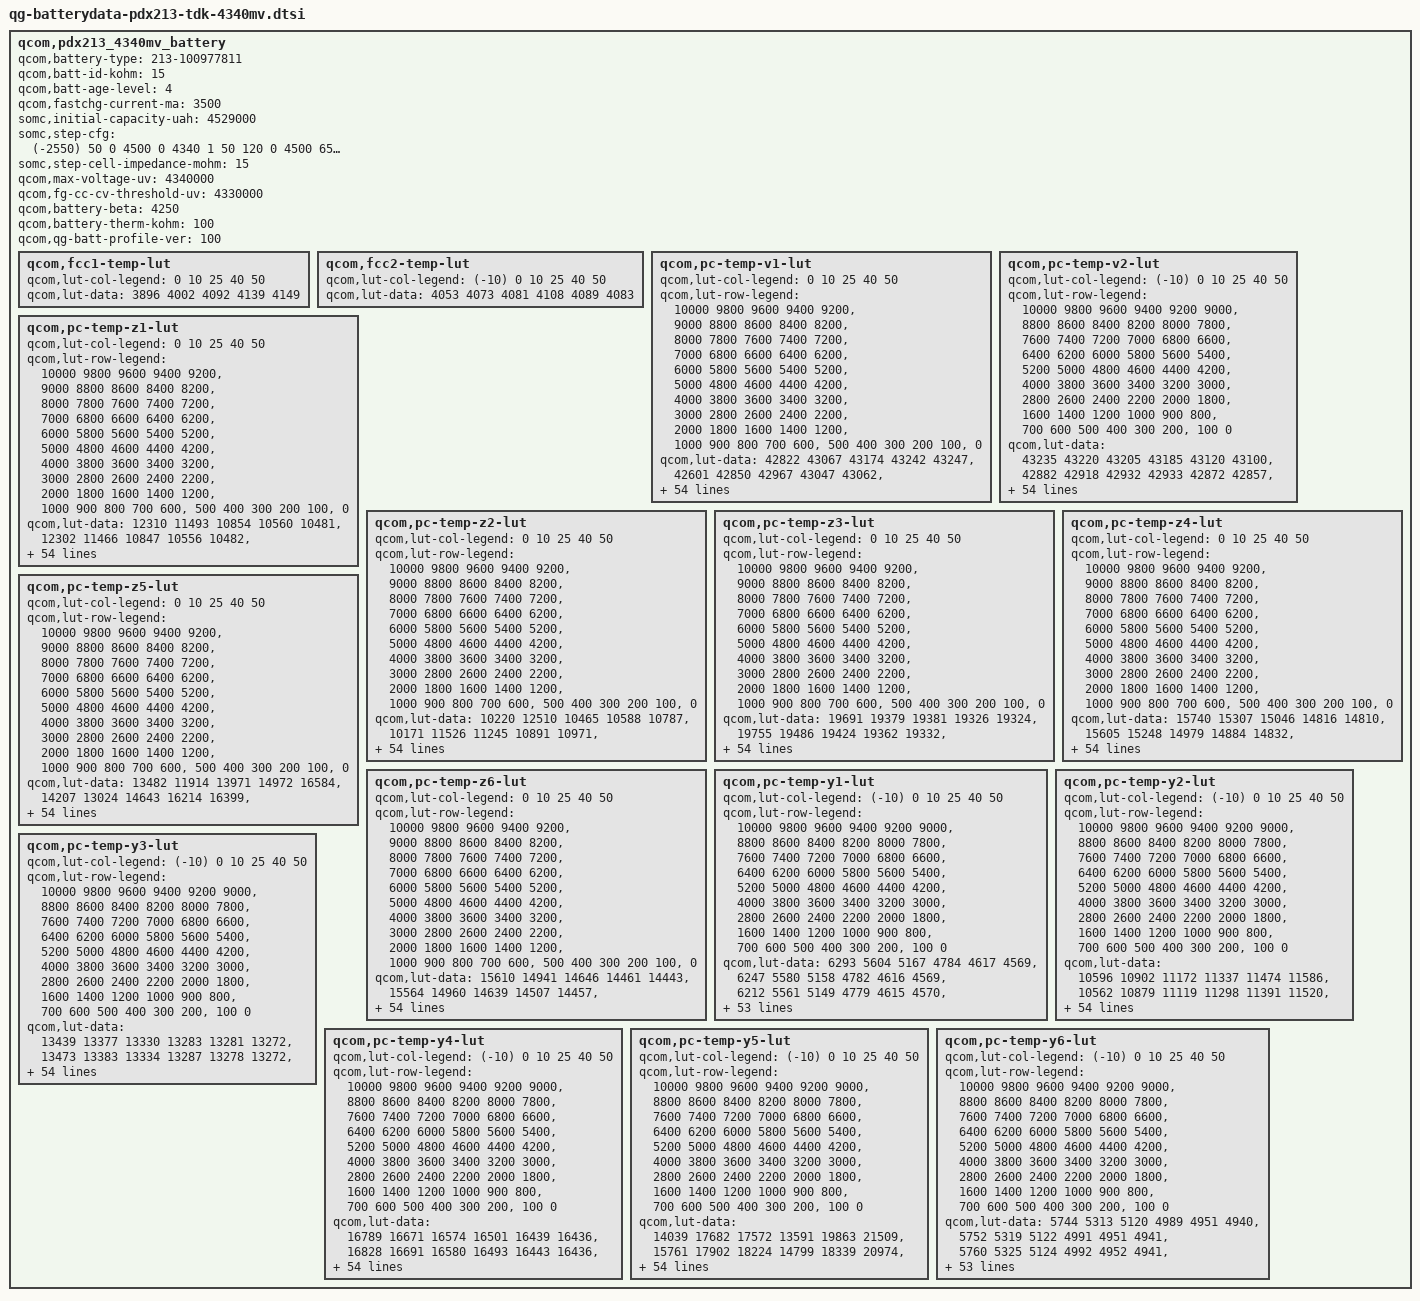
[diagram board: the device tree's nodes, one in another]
qcom,pdx213_4340mv_battery {
	/* Added or Modified by SOMC */
	qcom,battery-type = "213-100977811";
	qcom,batt-id-kohm = <15>;
	qcom,batt-age-level = <4>;
	qcom,fastchg-current-ma = <3500>;
	somc,initial-capacity-uah = <4529000>;
	somc,step-cfg = <
		(-2550) 50    0 4500    0 4340 1
		   50  120    0 4500  650 4340 2
		  120  150    0 4100 1950 4340 3
		  120  150 4100 4200 1500 4340 3
		  120  150 4200 4500  850 4340 3
		  150  200    0 4100 2150 4340 3
		  150  200 4100 4200 1750 4340 3
		  150  200 4200 4300 1500 4340 3
		  150  200 4300 4500 1050 4340 3
		  200  450    0 4150 3250 4340 3
		  200  450 4150 4200 2400 4340 3
		  200  450 4200 4300 1300 4340 3
		  200  450 4300 4500 1050 4340 3
		  450  550    0 4500 1300 4200 4
		  550 2550    0 4500    0 4200 5
	>;
	somc,step-cell-impedance-mohm = <15>;

	/* Prepared by Qualcomm */
    /* 4764147_SoMC_Licht_4129mAh_averaged_MasterSlave_Sept1st2020 */
    qcom,max-voltage-uv = <4340000>;
    qcom,fg-cc-cv-threshold-uv = <4330000>;
    /* qcom,fastchg-current-ma = <1500>; */
    /* qcom,batt-id-kohm = <0>; */
    qcom,battery-beta = <4250>;
    qcom,battery-therm-kohm = <100>;
    /* qcom,battery-type = "4764147_SoMC_Licht_4129mAh_averaged_MasterSlave_Sept1st2020"; */
    qcom,qg-batt-profile-ver = <100>;

	qcom,fcc1-temp-lut {
		qcom,lut-col-legend = <0 10 25 40 50>;
		qcom,lut-data = <3896 4002 4092 4139 4149>;
	};

	qcom,fcc2-temp-lut {
		qcom,lut-col-legend = <(-10) 0 10 25 40 50>;
		qcom,lut-data = <4053 4073 4081 4108 4089 4083>;
	};

	qcom,pc-temp-v1-lut {
		qcom,lut-col-legend = <0 10 25 40 50>;
		qcom,lut-row-legend = <10000 9800 9600 9400 9200>,
			<9000 8800 8600 8400 8200>,
			<8000 7800 7600 7400 7200>,
			<7000 6800 6600 6400 6200>,
			<6000 5800 5600 5400 5200>,
			<5000 4800 4600 4400 4200>,
			<4000 3800 3600 3400 3200>,
			<3000 2800 2600 2400 2200>,
			<2000 1800 1600 1400 1200>,
			<1000 900 800 700 600>,
			<500 400 300 200 100>,
			<0>;
		qcom,lut-data = <42822 43067 43174 43242 43247>,
			<42601 42850 42967 43047 43062>,
			<42385 42622 42754 42833 42849>,
			<42175 42391 42530 42618 42633>,
			<41968 42170 42302 42398 42415>,
			<41765 41955 42081 42176 42195>,
			<41565 41746 41866 41957 41977>,
			<41369 41540 41655 41738 41760>,
			<41181 41341 41450 41526 41547>,
			<41002 41146 41247 41318 41339>,
			<40826 40958 41049 41115 41135>,
			<40641 40774 40855 40917 40937>,
			<40451 40593 40666 40723 40742>,
			<40277 40414 40487 40539 40556>,
			<40126 40248 40315 40362 40377>,
			<39986 40102 40151 40192 40205>,
			<39851 39962 40001 40037 40045>,
			<39726 39812 39848 39887 39894>,
			<39596 39656 39668 39713 39724>,
			<39445 39482 39468 39501 39523>,
			<39277 39244 39276 39297 39323>,
			<39113 38986 39079 39122 39143>,
			<38942 38842 38909 38966 38977>,
			<38786 38769 38801 38835 38839>,
			<38688 38710 38721 38727 38726>,
			<38621 38648 38641 38629 38627>,
			<38568 38589 38555 38538 38535>,
			<38525 38528 38474 38452 38450>,
			<38488 38467 38405 38375 38370>,
			<38452 38406 38342 38302 38294>,
			<38412 38352 38287 38238 38224>,
			<38373 38302 38236 38180 38161>,
			<38336 38256 38190 38128 38103>,
			<38301 38217 38145 38077 38045>,
			<38265 38182 38103 38030 37991>,
			<38229 38142 38059 37980 37934>,
			<38190 38103 38018 37924 37867>,
			<38137 38054 37972 37861 37794>,
			<38051 37974 37903 37787 37714>,
			<37942 37862 37799 37697 37626>,
			<37824 37742 37683 37595 37526>,
			<37689 37611 37556 37473 37402>,
			<37541 37467 37417 37336 37265>,
			<37384 37304 37258 37184 37118>,
			<37266 37186 37136 37069 37009>,
			<37185 37119 37072 37008 36948>,
			<37166 37098 37054 36994 36931>,
			<37148 37078 37040 36979 36918>,
			<37115 37053 37022 36959 36902>,
			<37051 37000 36966 36894 36824>,
			<36830 36760 36701 36604 36516>,
			<36386 36326 36271 36173 36085>,
			<35820 35763 35715 35615 35530>,
			<35053 34997 34964 34863 34782>,
			<33752 33749 33817 33717 33648>,
			<30000 30000 30000 30000 30000>;
	};

	qcom,pc-temp-v2-lut {
		qcom,lut-col-legend = <(-10) 0 10 25 40 50>;
		qcom,lut-row-legend = <10000 9800 9600 9400 9200 9000>,
			<8800 8600 8400 8200 8000 7800>,
			<7600 7400 7200 7000 6800 6600>,
			<6400 6200 6000 5800 5600 5400>,
			<5200 5000 4800 4600 4400 4200>,
			<4000 3800 3600 3400 3200 3000>,
			<2800 2600 2400 2200 2000 1800>,
			<1600 1400 1200 1000 900 800>,
			<700 600 500 400 300 200>,
			<100 0>;
		qcom,lut-data = <43235 43220 43205 43185 43120 43100>,
			<42882 42918 42932 42933 42872 42857>,
			<42563 42638 42673 42691 42633 42623>,
			<42283 42380 42430 42459 42403 42396>,
			<42041 42145 42204 42238 42183 42177>,
			<41806 41920 41983 42020 41968 41962>,
			<41542 41698 41763 41803 41754 41747>,
			<41282 41483 41547 41588 41543 41536>,
			<41105 41275 41337 41378 41337 41330>,
			<41002 41071 41130 41171 41134 41126>,
			<40888 40878 40930 40970 40935 40928>,
			<40653 40704 40738 40776 40742 40737>,
			<40312 40540 40553 40587 40555 40551>,
			<40045 40362 40375 40404 40375 40372>,
			<39859 40166 40210 40226 40202 40198>,
			<39687 39962 40039 40055 40035 40030>,
			<39490 39746 39838 39899 39881 39875>,
			<39281 39522 39618 39746 39731 39726>,
			<39074 39309 39405 39559 39550 39548>,
			<38860 39104 39193 39318 39314 39316>,
			<38661 38913 38999 39090 39087 39092>,
			<38504 38747 38840 38914 38918 38924>,
			<38368 38600 38703 38764 38776 38783>,
			<38266 38463 38579 38636 38654 38662>,
			<38196 38332 38467 38528 38549 38558>,
			<38141 38215 38365 38432 38455 38465>,
			<38087 38118 38272 38342 38367 38376>,
			<38036 38034 38188 38259 38287 38292>,
			<37987 37971 38106 38181 38212 38215>,
			<37939 37929 38024 38108 38142 38143>,
			<37892 37894 37949 38041 38078 38077>,
			<37843 37861 37885 37982 38017 38016>,
			<37791 37831 37830 37928 37962 37960>,
			<37736 37797 37784 37871 37897 37892>,
			<37681 37759 37752 37816 37815 37793>,
			<37624 37715 37721 37758 37726 37684>,
			<37559 37660 37682 37688 37639 37588>,
			<37482 37587 37636 37609 37551 37500>,
			<37399 37504 37577 37528 37464 37412>,
			<37308 37411 37492 37449 37383 37329>,
			<37210 37306 37384 37361 37299 37244>,
			<37116 37185 37264 37252 37190 37136>,
			<37030 37041 37124 37126 37062 37005>,
			<36944 36911 36982 36986 36947 36894>,
			<36858 36799 36856 36899 36868 36816>,
			<36761 36720 36793 36868 36846 36798>,
			<36708 36688 36765 36853 36833 36782>,
			<36652 36649 36734 36831 36809 36763>,
			<36583 36598 36670 36792 36783 36735>,
			<36484 36496 36564 36679 36673 36599>,
			<36306 36248 36284 36365 36322 36237>,
			<35949 35794 35802 35871 35841 35757>,
			<35380 35141 35159 35239 35213 35132>,
			<34490 34190 34290 34362 34365 34280>,
			<33143 32720 32916 33184 33128 33134>,
			<31124 29569 29519 29613 29671 29810>;
	};

	qcom,pc-temp-z1-lut {
		qcom,lut-col-legend = <0 10 25 40 50>;
		qcom,lut-row-legend = <10000 9800 9600 9400 9200>,
			<9000 8800 8600 8400 8200>,
			<8000 7800 7600 7400 7200>,
			<7000 6800 6600 6400 6200>,
			<6000 5800 5600 5400 5200>,
			<5000 4800 4600 4400 4200>,
			<4000 3800 3600 3400 3200>,
			<3000 2800 2600 2400 2200>,
			<2000 1800 1600 1400 1200>,
			<1000 900 800 700 600>,
			<500 400 300 200 100>,
			<0>;
		qcom,lut-data = <12310 11493 10854 10560 10481>,
			<12302 11466 10847 10556 10482>,
			<12291 11465 10841 10556 10481>,
			<12272 11465 10834 10555 10480>,
			<12239 11464 10827 10553 10479>,
			<12214 11453 10825 10552 10479>,
			<12211 11438 10824 10551 10478>,
			<12216 11423 10823 10550 10478>,
			<12212 11407 10822 10549 10478>,
			<12175 11402 10820 10549 10478>,
			<12141 11406 10820 10549 10479>,
			<12141 11411 10821 10549 10479>,
			<12144 11409 10822 10550 10480>,
			<12147 11400 10821 10550 10481>,
			<12152 11396 10820 10551 10481>,
			<12160 11396 10821 10552 10482>,
			<12163 11397 10823 10553 10483>,
			<12160 11398 10826 10555 10485>,
			<12157 11404 10829 10557 10486>,
			<12159 11410 10833 10558 10488>,
			<12167 11416 10837 10561 10490>,
			<12171 11424 10841 10563 10493>,
			<12169 11432 10846 10566 10496>,
			<12166 11442 10852 10569 10499>,
			<12170 11450 10857 10573 10501>,
			<12183 11447 10862 10576 10502>,
			<12193 11441 10866 10579 10504>,
			<12187 11438 10870 10582 10506>,
			<12174 11445 10875 10584 10507>,
			<12169 11455 10880 10587 10509>,
			<12182 11459 10884 10589 10512>,
			<12201 11465 10885 10591 10514>,
			<12208 11468 10886 10594 10516>,
			<12215 11468 10888 10596 10518>,
			<12218 11470 10891 10599 10519>,
			<12224 11476 10896 10601 10521>,
			<12236 11490 10902 10604 10523>,
			<12242 11502 10909 10607 10526>,
			<12253 11507 10916 10610 10528>,
			<12266 11513 10924 10612 10529>,
			<12272 11514 10929 10614 10530>,
			<12290 11514 10930 10617 10533>,
			<12293 11518 10932 10620 10535>,
			<12290 11538 10940 10623 10536>,
			<12320 11545 10948 10626 10538>,
			<12324 11528 10950 10627 10538>,
			<12323 11539 10956 10628 10540>,
			<12322 11544 10959 10630 10540>,
			<12321 11561 10953 10630 10541>,
			<12320 11551 10967 10635 10544>,
			<12321 11567 10979 10641 10550>,
			<12323 11586 10990 10651 10559>,
			<12387 11634 11011 10665 10570>,
			<12408 11666 11046 10687 10587>,
			<12408 11666 11046 10687 10587>,
			<12408 11666 11046 10687 10587>;
	};

	qcom,pc-temp-z2-lut {
		qcom,lut-col-legend = <0 10 25 40 50>;
		qcom,lut-row-legend = <10000 9800 9600 9400 9200>,
			<9000 8800 8600 8400 8200>,
			<8000 7800 7600 7400 7200>,
			<7000 6800 6600 6400 6200>,
			<6000 5800 5600 5400 5200>,
			<5000 4800 4600 4400 4200>,
			<4000 3800 3600 3400 3200>,
			<3000 2800 2600 2400 2200>,
			<2000 1800 1600 1400 1200>,
			<1000 900 800 700 600>,
			<500 400 300 200 100>,
			<0>;
		qcom,lut-data = <10220 12510 10465 10588 10787>,
			<10171 11526 11245 10891 10971>,
			<10132 10867 11570 11264 11496>,
			<10103 10388 11247 11367 11691>,
			<10078 10267 10622 11273 11577>,
			<10066 10247 10490 11190 11472>,
			<10061 10239 10843 11203 11476>,
			<10058 10247 11136 11237 11507>,
			<10058 10268 11083 11240 11520>,
			<10063 10287 10949 11177 11482>,
			<10072 10300 10911 11120 11445>,
			<10084 10313 11008 11121 11470>,
			<10102 10331 11119 11142 11527>,
			<10122 10353 11175 11122 11525>,
			<10143 10363 11223 10855 11137>,
			<10163 10363 11212 10632 10768>,
			<10175 10362 10899 10630 10757>,
			<10182 10367 10599 10632 10767>,
			<10189 10393 10605 10659 10786>,
			<10207 10411 10659 10837 10836>,
			<10237 10398 10675 10975 10910>,
			<10262 10374 10590 10905 11061>,
			<10280 10369 10504 10769 11274>,
			<10295 10382 10534 10746 11313>,
			<10306 10400 10634 10828 11094>,
			<10315 10419 10676 10890 10851>,
			<10320 10441 10666 10830 10727>,
			<10319 10450 10648 10717 10634>,
			<10316 10448 10622 10684 10597>,
			<10315 10445 10583 10678 10584>,
			<10319 10448 10568 10676 10587>,
			<10326 10459 10589 10699 10613>,
			<10332 10471 10623 10749 10663>,
			<10338 10483 10650 10792 10728>,
			<10345 10496 10681 10832 10827>,
			<10349 10507 10705 10880 10923>,
			<10353 10514 10724 10964 10991>,
			<10358 10523 10744 11056 11048>,
			<10365 10540 10768 11071 11081>,
			<10371 10560 10804 11036 11108>,
			<10370 10564 10824 11010 11120>,
			<10360 10548 10826 10999 11093>,
			<10360 10542 10825 10994 11042>,
			<10376 10555 10832 11068 10995>,
			<10541 10657 10872 11044 11004>,
			<10584 10671 10860 10921 11024>,
			<10313 10684 10817 10965 11050>,
			<10019 10716 10799 10926 11005>,
			<10002 10739 10772 10936 11148>,
			<9982 10757 10830 11023 11224>,
			<9927 10806 11010 10793 10714>,
			<9658 10786 10975 10684 10621>,
			<9724 10778 10924 10602 10570>,
			<9611 10609 10797 10511 10508>,
			<9611 10609 10797 10511 10508>,
			<9611 10609 10797 10511 10508>;
	};

	qcom,pc-temp-z3-lut {
		qcom,lut-col-legend = <0 10 25 40 50>;
		qcom,lut-row-legend = <10000 9800 9600 9400 9200>,
			<9000 8800 8600 8400 8200>,
			<8000 7800 7600 7400 7200>,
			<7000 6800 6600 6400 6200>,
			<6000 5800 5600 5400 5200>,
			<5000 4800 4600 4400 4200>,
			<4000 3800 3600 3400 3200>,
			<3000 2800 2600 2400 2200>,
			<2000 1800 1600 1400 1200>,
			<1000 900 800 700 600>,
			<500 400 300 200 100>,
			<0>;
		qcom,lut-data = <19691 19379 19381 19326 19324>,
			<19755 19486 19424 19362 19332>,
			<19797 19554 19453 19388 19360>,
			<19807 19603 19466 19398 19373>,
			<19812 19617 19474 19402 19374>,
			<19815 19621 19480 19403 19374>,
			<19815 19622 19487 19402 19372>,
			<19813 19616 19492 19399 19370>,
			<19807 19598 19492 19395 19368>,
			<19789 19588 19488 19384 19362>,
			<19774 19583 19485 19375 19357>,
			<19772 19579 19473 19373 19355>,
			<19772 19573 19462 19372 19353>,
			<19771 19565 19457 19368 19351>,
			<19758 19559 19454 19353 19339>,
			<19739 19555 19448 19340 19328>,
			<19733 19552 19429 19338 19324>,
			<19734 19552 19413 19336 19321>,
			<19736 19553 19420 19338 19321>,
			<19738 19556 19438 19355 19327>,
			<19742 19564 19445 19369 19336>,
			<19744 19576 19431 19356 19347>,
			<19748 19579 19415 19333 19360>,
			<19751 19565 19409 19333 19371>,
			<19751 19552 19405 19368 19380>,
			<19746 19553 19405 19395 19386>,
			<19739 19556 19435 19395 19380>,
			<19732 19560 19469 19394 19367>,
			<19724 19567 19470 19392 19358>,
			<19719 19574 19462 19386 19353>,
			<19717 19574 19453 19378 19348>,
			<19715 19570 19445 19372 19343>,
			<19713 19565 19438 19365 19338>,
			<19711 19559 19432 19359 19332>,
			<19707 19553 19427 19352 19326>,
			<19702 19548 19423 19349 19322>,
			<19696 19544 19420 19350 19322>,
			<19689 19541 19417 19352 19323>,
			<19681 19535 19413 19351 19323>,
			<19673 19530 19408 19345 19323>,
			<19667 19524 19404 19341 19322>,
			<19661 19520 19401 19341 19324>,
			<19651 19515 19399 19342 19327>,
			<19631 19507 19397 19347 19330>,
			<19545 19476 19390 19343 19325>,
			<19511 19458 19381 19334 19317>,
			<19404 19444 19378 19325 19317>,
			<19303 19430 19371 19324 19314>,
			<19299 19425 19365 19322 19301>,
			<19297 19423 19358 19321 19303>,
			<19293 19412 19341 19345 19338>,
			<19275 19344 19344 19350 19342>,
			<19305 19332 19343 19355 19344>,
			<19314 19338 19355 19359 19346>,
			<19314 19338 19355 19359 19346>,
			<19314 19338 19355 19359 19346>;
	};

	qcom,pc-temp-z4-lut {
		qcom,lut-col-legend = <0 10 25 40 50>;
		qcom,lut-row-legend = <10000 9800 9600 9400 9200>,
			<9000 8800 8600 8400 8200>,
			<8000 7800 7600 7400 7200>,
			<7000 6800 6600 6400 6200>,
			<6000 5800 5600 5400 5200>,
			<5000 4800 4600 4400 4200>,
			<4000 3800 3600 3400 3200>,
			<3000 2800 2600 2400 2200>,
			<2000 1800 1600 1400 1200>,
			<1000 900 800 700 600>,
			<500 400 300 200 100>,
			<0>;
		qcom,lut-data = <15740 15307 15046 14816 14810>,
			<15605 15248 14979 14884 14832>,
			<15484 15172 14924 14839 14798>,
			<15380 15089 14885 14800 14766>,
			<15287 15022 14853 14765 14740>,
			<15208 14964 14815 14738 14720>,
			<15143 14918 14764 14724 14708>,
			<15087 14886 14726 14713 14701>,
			<15042 14862 14708 14707 14694>,
			<15003 14846 14695 14703 14688>,
			<14973 14833 14689 14700 14682>,
			<14956 14825 14689 14690 14674>,
			<14944 14827 14689 14678 14663>,
			<14936 14836 14685 14674 14658>,
			<14930 14841 14679 14681 14662>,
			<14925 14820 14678 14687 14665>,
			<14913 14792 14691 14683 14662>,
			<14882 14789 14711 14677 14657>,
			<14857 14799 14733 14680 14659>,
			<14867 14818 14763 14717 14702>,
			<14904 14897 14803 14766 14746>,
			<14947 15020 14884 14817 14761>,
			<15010 15053 14949 14867 14770>,
			<15068 15035 14948 14871 14769>,
			<15078 15008 14927 14818 14744>,
			<15069 14979 14900 14767 14719>,
			<15055 14944 14850 14746 14712>,
			<15038 14915 14801 14730 14707>,
			<15016 14891 14784 14719 14702>,
			<14995 14871 14773 14710 14693>,
			<14978 14863 14767 14704 14685>,
			<14962 14857 14762 14698 14679>,
			<14949 14853 14759 14694 14673>,
			<14937 14849 14760 14694 14673>,
			<14926 14846 14762 14699 14678>,
			<14916 14841 14764 14706 14686>,
			<14906 14836 14766 14715 14700>,
			<14897 14832 14767 14726 14717>,
			<14891 14831 14771 14732 14720>,
			<14885 14830 14779 14737 14717>,
			<14874 14827 14783 14739 14713>,
			<14854 14811 14774 14735 14709>,
			<14834 14793 14763 14728 14705>,
			<14811 14778 14758 14726 14705>,
			<14770 14732 14731 14716 14701>,
			<14773 14706 14698 14694 14683>,
			<14881 14705 14682 14681 14665>,
			<14983 14705 14668 14658 14647>,
			<14981 14701 14661 14644 14641>,
			<14979 14702 14672 14654 14650>,
			<14986 14732 14721 14660 14643>,
			<15019 14811 14720 14657 14642>,
			<14999 14828 14721 14654 14641>,
			<15002 14830 14708 14651 14642>,
			<15002 14830 14708 14651 14642>,
			<15002 14830 14708 14651 14642>;
	};

	qcom,pc-temp-z5-lut {
		qcom,lut-col-legend = <0 10 25 40 50>;
		qcom,lut-row-legend = <10000 9800 9600 9400 9200>,
			<9000 8800 8600 8400 8200>,
			<8000 7800 7600 7400 7200>,
			<7000 6800 6600 6400 6200>,
			<6000 5800 5600 5400 5200>,
			<5000 4800 4600 4400 4200>,
			<4000 3800 3600 3400 3200>,
			<3000 2800 2600 2400 2200>,
			<2000 1800 1600 1400 1200>,
			<1000 900 800 700 600>,
			<500 400 300 200 100>,
			<0>;
		qcom,lut-data = <13482 11914 13971 14972 16584>,
			<14207 13024 14643 16214 16399>,
			<14838 14449 15461 17259 18113>,
			<15338 15975 16410 18138 19589>,
			<15743 17146 17535 19426 20872>,
			<16198 18076 19013 20774 22099>,
			<16884 18818 21397 21907 23179>,
			<17610 19377 23485 22891 24160>,
			<18046 19849 24696 23038 24441>,
			<18308 20333 25723 22229 24152>,
			<18632 20959 25996 21573 23867>,
			<19848 21416 25576 22480 24791>,
			<22366 21355 25310 24374 27148>,
			<23621 21019 25939 24598 27787>,
			<22657 20844 26870 21613 24985>,
			<21240 21349 27032 19126 22329>,
			<21163 22392 25209 19272 22449>,
			<23381 23751 23452 19913 23164>,
			<26425 26115 25972 21457 23954>,
			<29690 28469 32683 26951 25088>,
			<33514 30677 34936 30977 25873>,
			<35363 32718 28922 26213 23741>,
			<35820 32760 21783 17178 19006>,
			<36079 28236 19068 15057 17767>,
			<35777 23954 17339 16563 19796>,
			<33841 23409 16944 18390 21522>,
			<31665 23201 19744 19755 21274>,
			<30139 23216 23533 21075 20679>,
			<28791 25008 25550 22405 20609>,
			<28344 27628 26979 23741 21587>,
			<28587 29438 28246 25078 22925>,
			<29009 31061 29542 26716 24467>,
			<29480 31911 30582 28223 26066>,
			<30181 32106 31212 28471 26389>,
			<30623 32180 31822 28106 25933>,
			<30621 32136 32056 27813 25222>,
			<30581 31916 31255 27767 24076>,
			<30538 31621 29787 27707 22530>,
			<30475 31068 28150 26974 21374>,
			<30379 30208 25955 23287 20369>,
			<30184 29619 24518 20663 19863>,
			<29737 29198 23905 20636 20321>,
			<29286 28854 23539 20718 20868>,
			<28495 28550 23030 20731 20595>,
			<24254 29035 24170 20322 19232>,
			<19902 26567 25285 20269 18588>,
			<15016 22858 25731 19730 20490>,
			<11801 20262 25382 22564 23642>,
			<11720 19564 24215 26311 22005>,
			<11709 19464 21288 21764 19353>,
			<11693 17916 15517 21473 26953>,
			<11423 13259 15225 21811 27255>,
			<11631 12738 14794 23007 27342>,
			<11926 13009 15515 23571 26779>,
			<11926 13009 15515 23571 26779>,
			<11926 13009 15515 23571 26779>;
	};

	qcom,pc-temp-z6-lut {
		qcom,lut-col-legend = <0 10 25 40 50>;
		qcom,lut-row-legend = <10000 9800 9600 9400 9200>,
			<9000 8800 8600 8400 8200>,
			<8000 7800 7600 7400 7200>,
			<7000 6800 6600 6400 6200>,
			<6000 5800 5600 5400 5200>,
			<5000 4800 4600 4400 4200>,
			<4000 3800 3600 3400 3200>,
			<3000 2800 2600 2400 2200>,
			<2000 1800 1600 1400 1200>,
			<1000 900 800 700 600>,
			<500 400 300 200 100>,
			<0>;
		qcom,lut-data = <15610 14941 14646 14461 14443>,
			<15564 14960 14639 14507 14457>,
			<15517 14952 14631 14503 14457>,
			<15467 14932 14620 14497 14456>,
			<15416 14911 14607 14484 14446>,
			<15370 14884 14593 14471 14435>,
			<15332 14857 14576 14463 14429>,
			<15298 14834 14561 14458 14424>,
			<15265 14813 14551 14451 14419>,
			<15229 14800 14543 14444 14414>,
			<15202 14792 14536 14437 14408>,
			<15189 14786 14531 14432 14403>,
			<15182 14784 14527 14426 14398>,
			<15174 14782 14522 14421 14393>,
			<15165 14780 14518 14416 14388>,
			<15156 14769 14515 14412 14384>,
			<15147 14756 14513 14408 14380>,
			<15138 14755 14512 14405 14377>,
			<15132 14762 14520 14408 14377>,
			<15138 14773 14544 14434 14398>,
			<15160 14813 14569 14462 14423>,
			<15183 14873 14597 14478 14439>,
			<15214 14888 14617 14489 14452>,
			<15242 14876 14615 14491 14454>,
			<15247 14860 14604 14486 14450>,
			<15242 14847 14596 14480 14443>,
			<15235 14836 14592 14474 14436>,
			<15225 14828 14588 14466 14428>,
			<15213 14823 14582 14459 14421>,
			<15204 14820 14574 14453 14415>,
			<15199 14817 14567 14446 14409>,
			<15195 14814 14561 14440 14403>,
			<15192 14812 14556 14434 14397>,
			<15190 14808 14554 14432 14395>,
			<15188 14805 14553 14431 14395>,
			<15185 14804 14553 14431 14395>,
			<15183 14803 14552 14435 14400>,
			<15182 14802 14552 14442 14408>,
			<15183 14802 14553 14444 14410>,
			<15184 14803 14555 14443 14409>,
			<15184 14803 14556 14443 14407>,
			<15182 14799 14552 14441 14407>,
			<15180 14794 14547 14440 14407>,
			<15172 14788 14545 14441 14409>,
			<15131 14763 14533 14436 14405>,
			<15120 14744 14515 14421 14393>,
			<15113 14738 14507 14411 14385>,
			<15109 14734 14498 14401 14375>,
			<15112 14734 14492 14394 14366>,
			<15120 14737 14496 14398 14371>,
			<15133 14753 14511 14415 14389>,
			<15154 14761 14515 14419 14392>,
			<15180 14773 14520 14422 14395>,
			<15217 14796 14528 14427 14400>,
			<15217 14796 14528 14427 14400>,
			<15217 14796 14528 14427 14400>;
	};

	qcom,pc-temp-y1-lut {
		qcom,lut-col-legend = <(-10) 0 10 25 40 50>;
		qcom,lut-row-legend = <10000 9800 9600 9400 9200 9000>,
			<8800 8600 8400 8200 8000 7800>,
			<7600 7400 7200 7000 6800 6600>,
			<6400 6200 6000 5800 5600 5400>,
			<5200 5000 4800 4600 4400 4200>,
			<4000 3800 3600 3400 3200 3000>,
			<2800 2600 2400 2200 2000 1800>,
			<1600 1400 1200 1000 900 800>,
			<700 600 500 400 300 200>,
			<100 0>;
		qcom,lut-data = <6293 5604 5167 4784 4617 4569>,
			<6247 5580 5158 4782 4616 4569>,
			<6212 5561 5149 4779 4615 4570>,
			<6188 5546 5142 4776 4614 4571>,
			<6173 5537 5138 4774 4613 4571>,
			<6168 5533 5136 4772 4613 4572>,
			<6177 5542 5137 4771 4612 4572>,
			<6196 5559 5140 4770 4612 4572>,
			<6200 5562 5138 4770 4612 4572>,
			<6192 5553 5132 4769 4612 4571>,
			<6179 5546 5127 4768 4612 4571>,
			<6159 5549 5127 4768 4612 4571>,
			<6132 5557 5129 4769 4612 4573>,
			<6125 5561 5129 4770 4613 4573>,
			<6158 5561 5128 4770 4614 4573>,
			<6192 5559 5127 4770 4614 4573>,
			<6195 5558 5125 4770 4614 4573>,
			<6184 5558 5122 4772 4613 4574>,
			<6178 5558 5123 4773 4613 4575>,
			<6177 5565 5127 4776 4616 4575>,
			<6176 5571 5132 4778 4618 4575>,
			<6170 5573 5135 4781 4619 4575>,
			<6156 5577 5137 4783 4619 4576>,
			<6149 5576 5139 4785 4619 4577>,
			<6149 5563 5142 4788 4621 4578>,
			<6150 5550 5144 4791 4622 4579>,
			<6153 5549 5147 4793 4624 4580>,
			<6158 5551 5150 4795 4626 4582>,
			<6162 5553 5153 4797 4628 4583>,
			<6162 5569 5155 4801 4630 4584>,
			<6161 5590 5157 4806 4631 4585>,
			<6154 5595 5158 4811 4633 4586>,
			<6129 5592 5158 4816 4634 4588>,
			<6111 5590 5158 4819 4635 4589>,
			<6123 5582 5160 4820 4637 4590>,
			<6148 5572 5163 4821 4640 4592>,
			<6158 5571 5166 4823 4641 4592>,
			<6154 5575 5173 4826 4642 4593>,
			<6150 5578 5181 4827 4643 4594>,
			<6146 5570 5188 4830 4644 4595>,
			<6138 5557 5194 4833 4646 4596>,
			<6137 5557 5194 4837 4646 4596>,
			<6156 5569 5188 4842 4647 4597>,
			<6168 5568 5190 4847 4649 4598>,
			<6197 5558 5200 4852 4652 4599>,
			<6175 5581 5194 4856 4653 4600>,
			<6182 5578 5198 4852 4654 4602>,
			<6241 5588 5203 4852 4654 4601>,
			<6260 5631 5199 4856 4654 4601>,
			<6290 5637 5191 4861 4655 4603>,
			<6371 5649 5193 4865 4656 4603>,
			<6441 5690 5216 4874 4660 4606>,
			<6490 5739 5228 4886 4667 4612>,
			<6514 5784 5289 4903 4677 4619>,
			<6514 5784 5289 4903 4677 4619>,
			<6514 5784 5289 4903 4677 4619>;
	};

	qcom,pc-temp-y2-lut {
		qcom,lut-col-legend = <(-10) 0 10 25 40 50>;
		qcom,lut-row-legend = <10000 9800 9600 9400 9200 9000>,
			<8800 8600 8400 8200 8000 7800>,
			<7600 7400 7200 7000 6800 6600>,
			<6400 6200 6000 5800 5600 5400>,
			<5200 5000 4800 4600 4400 4200>,
			<4000 3800 3600 3400 3200 3000>,
			<2800 2600 2400 2200 2000 1800>,
			<1600 1400 1200 1000 900 800>,
			<700 600 500 400 300 200>,
			<100 0>;
		qcom,lut-data = <10596 10902 11172 11337 11474 11586>,
			<10562 10879 11119 11298 11391 11520>,
			<10542 10854 11068 11258 11312 11443>,
			<10531 10830 11021 11220 11245 11366>,
			<10528 10807 10979 11186 11199 11301>,
			<10530 10788 10944 11157 11180 11260>,
			<10585 10767 10913 11128 11197 11238>,
			<10688 10750 10887 11105 11225 11223>,
			<10716 10753 10882 11102 11231 11220>,
			<10702 10808 10883 11110 11220 11226>,
			<10690 10857 10886 11117 11211 11234>,
			<10717 10865 10915 11119 11221 11244>,
			<10786 10870 10982 11125 11246 11260>,
			<10831 10883 11038 11139 11270 11273>,
			<10862 10948 11087 11182 11292 11284>,
			<10881 11013 11128 11235 11322 11299>,
			<10879 11035 11160 11297 11399 11372>,
			<10863 11047 11185 11360 11510 11504>,
			<10831 11060 11201 11372 11539 11560>,
			<10585 11075 11210 11365 11508 11558>,
			<10293 11089 11218 11360 11478 11551>,
			<10143 11100 11230 11374 11475 11572>,
			<9855 11111 11243 11404 11483 11623>,
			<9703 11114 11258 11427 11499 11647>,
			<9693 11089 11275 11442 11540 11672>,
			<9688 11062 11292 11458 11594 11704>,
			<9684 11075 11313 11487 11650 11753>,
			<9680 11127 11334 11526 11716 11850>,
			<9677 11151 11342 11555 11768 11900>,
			<9674 11105 11331 11576 11824 11890>,
			<9672 11032 11315 11596 11880 11879>,
			<9671 10981 11306 11627 11938 11951>,
			<9669 10941 11297 11661 12022 12147>,
			<9668 10889 11286 11666 12050 12236>,
			<9667 10676 11261 11632 11911 12075>,
			<9666 10388 11229 11595 11742 11878>,
			<9665 10217 11200 11577 11693 11851>,
			<9664 9923 11172 11560 11666 11854>,
			<9664 9738 11136 11542 11654 11854>,
			<9663 9707 11080 11523 11673 11825>,
			<9662 9690 11009 11504 11699 11784>,
			<9661 9680 10934 11481 11708 11765>,
			<9661 9674 10849 11451 11713 11750>,
			<9660 9670 10677 11364 11648 11704>,
			<9658 9666 10377 11258 11493 11578>,
			<9656 9664 10230 11264 11400 11370>,
			<9655 9663 10201 11300 11442 11324>,
			<9654 9662 10147 11282 11391 11341>,
			<9653 9660 9820 11250 11426 11457>,
			<9651 9658 9732 11239 11424 11425>,
			<9650 9655 9697 11193 11316 11286>,
			<9649 9652 9674 11105 11299 11213>,
			<9648 9650 9663 10996 11158 11132>,
			<9648 9649 9655 10889 11096 10999>,
			<9648 9649 9655 10889 11096 10999>,
			<9648 9649 9655 10889 11096 10999>;
	};

	qcom,pc-temp-y3-lut {
		qcom,lut-col-legend = <(-10) 0 10 25 40 50>;
		qcom,lut-row-legend = <10000 9800 9600 9400 9200 9000>,
			<8800 8600 8400 8200 8000 7800>,
			<7600 7400 7200 7000 6800 6600>,
			<6400 6200 6000 5800 5600 5400>,
			<5200 5000 4800 4600 4400 4200>,
			<4000 3800 3600 3400 3200 3000>,
			<2800 2600 2400 2200 2000 1800>,
			<1600 1400 1200 1000 900 800>,
			<700 600 500 400 300 200>,
			<100 0>;
		qcom,lut-data = <13439 13377 13330 13283 13281 13272>,
			<13473 13383 13334 13287 13278 13272>,
			<13495 13389 13337 13290 13277 13273>,
			<13506 13396 13340 13294 13277 13274>,
			<13510 13401 13343 13297 13278 13275>,
			<13511 13405 13345 13299 13279 13275>,
			<13499 13407 13348 13300 13282 13276>,
			<13477 13409 13350 13301 13285 13277>,
			<13471 13409 13352 13301 13287 13278>,
			<13475 13405 13354 13302 13288 13278>,
			<13479 13402 13356 13303 13288 13279>,
			<13478 13399 13353 13304 13289 13281>,
			<13476 13397 13347 13306 13289 13284>,
			<13473 13396 13345 13306 13290 13285>,
			<13465 13396 13347 13305 13292 13285>,
			<13455 13396 13348 13305 13294 13285>,
			<13445 13392 13347 13305 13294 13285>,
			<13434 13384 13342 13304 13294 13287>,
			<13427 13377 13338 13304 13292 13287>,
			<13423 13371 13333 13300 13286 13281>,
			<13420 13366 13329 13297 13281 13275>,
			<13413 13361 13327 13295 13279 13273>,
			<13399 13356 13325 13293 13278 13272>,
			<13392 13352 13323 13292 13278 13272>,
			<13400 13349 13322 13292 13277 13273>,
			<13416 13346 13321 13292 13277 13274>,
			<13432 13338 13320 13292 13277 13274>,
			<13454 13326 13319 13293 13277 13273>,
			<13479 13320 13319 13293 13277 13273>,
			<13506 13324 13318 13293 13277 13273>,
			<13537 13331 13318 13293 13278 13273>,
			<13570 13338 13317 13292 13279 13273>,
			<13605 13345 13316 13292 13280 13274>,
			<13644 13352 13316 13292 13281 13275>,
			<13691 13358 13318 13292 13279 13273>,
			<13745 13364 13322 13293 13277 13272>,
			<13801 13373 13325 13293 13276 13272>,
			<13860 13386 13328 13292 13275 13272>,
			<13921 13403 13330 13291 13275 13272>,
			<13982 13423 13331 13291 13276 13272>,
			<14045 13450 13332 13291 13276 13274>,
			<14115 13482 13334 13292 13276 13274>,
			<14192 13526 13336 13294 13276 13274>,
			<14286 13583 13339 13294 13276 13274>,
			<14411 13665 13342 13295 13277 13272>,
			<14714 13776 13354 13300 13282 13280>,
			<14824 13795 13353 13301 13284 13281>,
			<14952 13877 13364 13305 13285 13284>,
			<15496 14008 13377 13311 13292 13286>,
			<16388 14193 13415 13313 13291 13283>,
			<18114 14617 13458 13310 13285 13279>,
			<21965 15684 13547 13313 13287 13281>,
			<33011 18685 13769 13320 13288 13283>,
			<65535 28874 14566 13328 13293 13287>,
			<65535 28874 14566 13328 13293 13287>,
			<65535 28874 14566 13328 13293 13287>;
	};

	qcom,pc-temp-y4-lut {
		qcom,lut-col-legend = <(-10) 0 10 25 40 50>;
		qcom,lut-row-legend = <10000 9800 9600 9400 9200 9000>,
			<8800 8600 8400 8200 8000 7800>,
			<7600 7400 7200 7000 6800 6600>,
			<6400 6200 6000 5800 5600 5400>,
			<5200 5000 4800 4600 4400 4200>,
			<4000 3800 3600 3400 3200 3000>,
			<2800 2600 2400 2200 2000 1800>,
			<1600 1400 1200 1000 900 800>,
			<700 600 500 400 300 200>,
			<100 0>;
		qcom,lut-data = <16789 16671 16574 16501 16439 16436>,
			<16828 16691 16580 16493 16443 16436>,
			<16869 16710 16586 16487 16446 16436>,
			<16910 16728 16592 16484 16448 16437>,
			<16949 16743 16597 16482 16450 16438>,
			<16983 16756 16601 16482 16450 16439>,
			<17012 16765 16603 16484 16449 16440>,
			<17040 16773 16605 16488 16448 16442>,
			<17084 16787 16608 16493 16448 16445>,
			<17180 16815 16613 16498 16452 16448>,
			<17252 16848 16621 16504 16457 16452>,
			<17180 16885 16650 16511 16463 16454>,
			<17006 16922 16699 16519 16470 16456>,
			<16933 16929 16726 16529 16476 16459>,
			<16927 16901 16741 16542 16482 16467>,
			<16923 16860 16749 16559 16489 16478>,
			<16901 16824 16735 16584 16507 16492>,
			<16855 16786 16697 16611 16532 16508>,
			<16807 16747 16658 16611 16537 16511>,
			<16751 16705 16613 16565 16511 16491>,
			<16708 16667 16576 16519 16482 16468>,
			<16709 16641 16559 16497 16467 16457>,
			<16730 16621 16549 16482 16455 16448>,
			<16744 16600 16544 16479 16453 16445>,
			<16747 16569 16541 16482 16457 16447>,
			<16747 16546 16539 16486 16463 16451>,
			<16746 16547 16539 16491 16470 16456>,
			<16746 16558 16540 16497 16479 16466>,
			<16745 16567 16539 16504 16489 16476>,
			<16745 16571 16529 16512 16501 16486>,
			<16746 16576 16517 16521 16511 16495>,
			<16749 16583 16516 16532 16518 16504>,
			<16755 16594 16517 16543 16523 16512>,
			<16759 16608 16520 16546 16524 16514>,
			<16760 16633 16533 16542 16513 16498>,
			<16760 16662 16555 16535 16497 16477>,
			<16760 16682 16576 16521 16485 16469>,
			<16757 16701 16598 16500 16473 16464>,
			<16755 16712 16613 16494 16469 16462>,
			<16756 16714 16619 16497 16470 16462>,
			<16758 16715 16623 16501 16471 16462>,
			<16762 16710 16624 16505 16470 16461>,
			<16769 16683 16623 16509 16469 16459>,
			<16782 16675 16620 16500 16461 16452>,
			<16820 16676 16617 16496 16448 16441>,
			<16930 16705 16640 16505 16464 16449>,
			<16941 16706 16634 16508 16467 16454>,
			<16931 16729 16658 16524 16479 16469>,
			<17088 16769 16704 16544 16506 16522>,
			<17331 16799 16744 16553 16528 16516>,
			<17752 16879 16737 16528 16457 16447>,
			<18911 17199 16738 16520 16452 16447>,
			<24363 18753 16791 16547 16462 16455>,
			<65535 32540 17299 16594 16493 16483>,
			<65535 32540 17299 16594 16493 16483>,
			<65535 32540 17299 16594 16493 16483>;
	};

	qcom,pc-temp-y5-lut {
		qcom,lut-col-legend = <(-10) 0 10 25 40 50>;
		qcom,lut-row-legend = <10000 9800 9600 9400 9200 9000>,
			<8800 8600 8400 8200 8000 7800>,
			<7600 7400 7200 7000 6800 6600>,
			<6400 6200 6000 5800 5600 5400>,
			<5200 5000 4800 4600 4400 4200>,
			<4000 3800 3600 3400 3200 3000>,
			<2800 2600 2400 2200 2000 1800>,
			<1600 1400 1200 1000 900 800>,
			<700 600 500 400 300 200>,
			<100 0>;
		qcom,lut-data = <14039 17682 17572 13591 19863 21509>,
			<15761 17902 18224 14799 18339 20974>,
			<16818 18124 18601 15919 17410 20388>,
			<17372 18319 18763 16842 16927 19796>,
			<17586 18460 18769 17454 16745 19243>,
			<17622 18519 18678 17645 16717 18773>,
			<16749 18446 18419 17325 17744 18395>,
			<15087 18252 18001 16746 19509 18027>,
			<14869 17878 17654 16263 19842 17552>,
			<17323 16609 17386 15804 19139 16842>,
			<19878 15646 17059 15462 18243 16404>,
			<20844 16384 16285 15231 17302 16874>,
			<21482 18215 15266 15040 16375 17806>,
			<21656 19628 15166 14908 16168 17938>,
			<21911 20790 16958 14448 16284 16733>,
			<22232 21681 19168 14112 16379 15685>,
			<22419 22131 20843 14300 16093 15624>,
			<22646 22439 22356 14846 15489 15626>,
			<22792 22764 22837 15917 15508 15800>,
			<21456 23199 22839 18939 17667 17480>,
			<19533 23502 22803 21142 19769 19034>,
			<17733 23464 22793 21188 20179 18995>,
			<13966 23306 22768 21016 20371 18715>,
			<12038 23218 22727 20785 20252 18613>,
			<12060 23152 22624 20303 18994 18797>,
			<12166 22737 22564 19968 17711 18974>,
			<12284 20612 22803 20163 17404 18429>,
			<12459 15946 23445 20554 17241 16928>,
			<12647 13821 24073 20675 17205 16227>,
			<12880 14242 24863 20667 17338 16147>,
			<13135 15013 25499 20667 17606 16108>,
			<13279 15882 24855 20792 18358 16376>,
			<13359 17090 22480 21120 19834 17283>,
			<13460 17988 21071 21659 20426 17838>,
			<13746 18130 20925 23042 20052 17959>,
			<14136 17893 20969 24108 19560 18049>,
			<14264 17561 20908 23815 19343 18187>,
			<14233 16425 20629 22872 19207 18372>,
			<14151 15638 20290 21841 19045 18615>,
			<13842 15500 19517 20320 18760 18977>,
			<13269 15406 18660 19116 18466 19461>,
			<13072 15275 18519 18766 18291 20141>,
			<13172 15058 18542 18546 18164 21032>,
			<13264 14771 18321 18615 18855 20345>,
			<13315 14394 17365 18706 20111 18308>,
			<12857 14066 16507 18364 17182 19452>,
			<12742 14059 16061 18131 17142 18876>,
			<12704 14004 15734 17518 16734 21584>,
			<12154 14156 14083 18205 21643 20813>,
			<11532 14323 14319 19227 19689 18332>,
			<10867 13405 14433 20158 19979 21248>,
			<9769 11555 14396 21780 23214 23976>,
			<9121 9936 13969 22412 22873 24266>,
			<8818 9054 11650 22975 26032 26296>,
			<8818 9054 11650 22975 26032 26296>,
			<8818 9054 11650 22975 26032 26296>;
	};

	qcom,pc-temp-y6-lut {
		qcom,lut-col-legend = <(-10) 0 10 25 40 50>;
		qcom,lut-row-legend = <10000 9800 9600 9400 9200 9000>,
			<8800 8600 8400 8200 8000 7800>,
			<7600 7400 7200 7000 6800 6600>,
			<6400 6200 6000 5800 5600 5400>,
			<5200 5000 4800 4600 4400 4200>,
			<4000 3800 3600 3400 3200 3000>,
			<2800 2600 2400 2200 2000 1800>,
			<1600 1400 1200 1000 900 800>,
			<700 600 500 400 300 200>,
			<100 0>;
		qcom,lut-data = <5744 5313 5120 4989 4951 4940>,
			<5752 5319 5122 4991 4951 4941>,
			<5760 5325 5124 4992 4952 4941>,
			<5766 5331 5126 4994 4953 4942>,
			<5770 5336 5128 4995 4954 4943>,
			<5772 5340 5130 4996 4955 4944>,
			<5770 5342 5131 4998 4956 4945>,
			<5767 5343 5132 4999 4958 4947>,
			<5770 5346 5133 5001 4960 4948>,
			<5803 5350 5135 5003 4962 4949>,
			<5833 5355 5137 5005 4963 4951>,
			<5815 5364 5143 5008 4965 4953>,
			<5769 5373 5152 5011 4968 4956>,
			<5748 5375 5158 5014 4970 4958>,
			<5748 5368 5163 5018 4973 4960>,
			<5748 5358 5165 5022 4977 4963>,
			<5742 5346 5161 5029 4982 4967>,
			<5732 5331 5147 5036 4988 4972>,
			<5719 5317 5133 5036 4989 4973>,
			<5701 5303 5117 5020 4977 4963>,
			<5685 5291 5104 5005 4965 4952>,
			<5682 5283 5098 4997 4959 4948>,
			<5685 5277 5095 4992 4955 4944>,
			<5691 5273 5094 4991 4954 4943>,
			<5707 5268 5093 4991 4955 4944>,
			<5732 5264 5093 4993 4956 4946>,
			<5757 5264 5094 4995 4958 4948>,
			<5783 5267 5096 4997 4961 4950>,
			<5812 5272 5096 5000 4965 4953>,
			<5841 5284 5095 5003 4968 4955>,
			<5872 5303 5094 5006 4972 4958>,
			<5906 5322 5094 5009 4975 4961>,
			<5941 5345 5097 5013 4977 4965>,
			<5979 5371 5100 5014 4978 4966>,
			<6020 5399 5109 5014 4974 4960>,
			<6065 5430 5121 5013 4968 4953>,
			<6112 5460 5134 5009 4964 4951>,
			<6163 5491 5150 5003 4960 4950>,
			<6216 5524 5165 5001 4959 4949>,
			<6270 5562 5180 5003 4960 4950>,
			<6326 5602 5194 5005 4960 4951>,
			<6389 5645 5212 5008 4961 4951>,
			<6460 5691 5234 5011 4960 4950>,
			<6549 5750 5258 5010 4958 4948>,
			<6678 5831 5287 5011 4955 4944>,
			<6995 5947 5333 5018 4964 4953>,
			<7108 5972 5324 5020 4966 4954>,
			<7229 6051 5360 5028 4970 4961>,
			<7738 6182 5405 5039 4983 4977>,
			<8534 6357 5473 5043 4988 4974>,
			<9998 6767 5536 5035 4964 4952>,
			<13183 7752 5655 5038 4964 4954>,
			<22365 10452 5907 5056 4969 4958>,
			<65535 21503 6778 5081 4983 4969>,
			<65535 21503 6778 5081 4983 4969>,
			<65535 21503 6778 5081 4983 4969>;
	};

};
